# CY8C4248AZI_L485 register map
File version: 0.1
PSoC 4200L
Registers are 32-bit, read-write, no defined reset value unless marked. A register's access mark holds for its fields unless they carry their own. Offsets are from the block's base; lines under a group give offsets from that group; [hi:lo] are bit positions; {n}, {i} and the like mark numbered series; 'fields as' and 'values as' point back to an identical list; <NAME> marks a mode.

## Memory map
0x00000000 QuadDec
0x00000000 QuadDec_Cnt16
0x00000000 Timer_PWM
0x00000000 ADC_SAR_Seq_1 — Sequencing SAR ADC
0x00000000 PWM_Motor
0x00000000 I2C — Serial Communication Block
0x00000000 DMAC — DMAC Registers
0x00000000 Status_Reg_Switches
0x00000000 CAN
0x00000000 Can_addr
0x00000000 UART — Serial Communication Block

## QuadDec
Base 0x00000000
0x400F0002 QuadDec_Cnt16_COUNTER 16-bit — Counter value
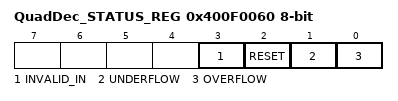
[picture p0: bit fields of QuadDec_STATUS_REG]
0x400F0060 QuadDec_STATUS_REG 8-bit — Quadrature Decoder Status Register
  [3] INVALID_IN ro — Invalid state transition on the A and B inputs
  [2] RESET ro — Counter Reset due index
  [1] UNDERFLOW ro — Counter underflow
  [0] OVERFLOW ro — Counter overflow

## QuadDec_Cnt16
Base 0x00000000; alternate view of QuadDec
0x400F0002 QuadDec_Cnt16_COUNTER 16-bit — UDB.A0 - Current Counter Value
0x400F0022 QuadDec_Cnt16_PERIOD 16-bit — UDB.D0 - Assigned Period
0x400F0032 QuadDec_Cnt16_COMPARE 16-bit — UDB.D1 - Assigned Compare Value
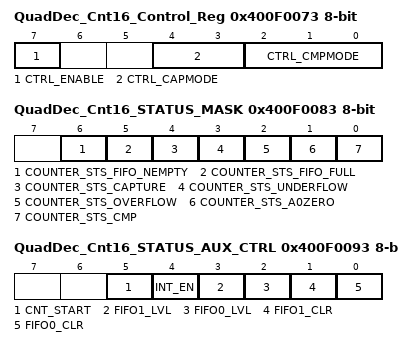
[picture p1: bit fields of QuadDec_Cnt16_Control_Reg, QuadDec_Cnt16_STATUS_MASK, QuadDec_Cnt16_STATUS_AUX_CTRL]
0x400F0073 QuadDec_Cnt16_Control_Reg 8-bit — UDB Control Register - Assigned Control Register Value
  [7] CTRL_ENABLE — Enable Counter
  [4:3] CTRL_CAPMODE — Capture mode
  [2:0] CTRL_CMPMODE — Compare mode
0x400F0083 QuadDec_Cnt16_STATUS_MASK 8-bit — UDB Status bits Interrupt Mask Enable Register
  [6] COUNTER_STS_FIFO_NEMPTY — FIFO Not Empty Status
  [5] COUNTER_STS_FIFO_FULL — FIFO Full Status
  [4] COUNTER_STS_CAPTURE — Capture Status
  [3] COUNTER_STS_UNDERFLOW — Underflow status
  [2] COUNTER_STS_OVERFLOW — Overflow status
  [1] COUNTER_STS_A0ZERO — A0 Zero ouput status
  [0] COUNTER_STS_CMP — Compare output status
0x400F0093 QuadDec_Cnt16_STATUS_AUX_CTRL 8-bit — UDB Auxilliary Control Register
  [5] CNT_START — FIFO0 clear
    0=E_CNT_START0 (Disable counter); 1=E_CNT_START1 (Enable counter)
  [4] INT_EN
    0=E_INT_EN0 (Interrupt disabled); 1=E_INT_EN1 (Interrupt enabled)
  [3] FIFO1_LVL — FIFO level
    0=E_FIFO_LVL_0 (FIFO LVL: input mode: FIFO not full; output mode: FIFO not empty); 1=E_FIFO_LVL_1 (FIFO LVL: input mode: FIFO at least 1/2 empty; output mode: FIFO at least 1/2 full)
  [2] FIFO0_LVL — FIFO level
    values as FIFO1_LVL
  [1] FIFO1_CLR — FIFO1 clear
    0=E_FIFO_CLR_0 (Normal FIFO operation); 1=E_FIFO_CLR_1 (Clear FIFO state)
  [0] FIFO0_CLR — FIFO0 clear
    values as FIFO1_CLR

## Timer_PWM
Base 0x00000000
0x400F0004 Timer_PWM_COUNTER 24-bit — UDB.A0 - Current Down Counter Value
0x400F0024 Timer_PWM_PERIOD 24-bit — UDB.D0 - Assigned Period
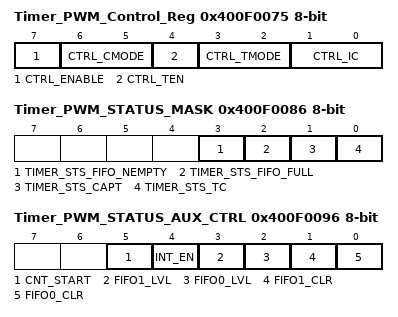
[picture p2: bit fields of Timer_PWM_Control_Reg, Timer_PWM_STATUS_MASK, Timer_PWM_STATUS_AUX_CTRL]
0x400F0075 Timer_PWM_Control_Reg 8-bit — UDB Control Register - Assigned Control Register Value
  [7] CTRL_ENABLE — Enable the Timer
  [6:5] CTRL_CMODE — Capture Mode
  [4] CTRL_TEN — Trigger Enable Bit
  [3:2] CTRL_TMODE — Trigger Mode
  [1:0] CTRL_IC — Interrupt Count
0x400F0086 Timer_PWM_STATUS_MASK 8-bit — UDB Status bits Interrupt Mask Enable Register
  [3] TIMER_STS_FIFO_NEMPTY ro — FIFO Empty status
  [2] TIMER_STS_FIFO_FULL ro — FIFO Full Status
  [1] TIMER_STS_CAPT ro — Enables the Interrupt on Capture
  [0] TIMER_STS_TC ro — Enables the Interrupt on TC
0x400F0096 Timer_PWM_STATUS_AUX_CTRL 8-bit — UDB Auxilliary Control Register
  [5] CNT_START — FIFO0 clear
    0=E_CNT_START0 (Disable counter); 1=E_CNT_START1 (Enable counter)
  [4] INT_EN
    0=E_INT_EN0 (Interrupt disabled); 1=E_INT_EN1 (Interrupt enabled)
  [3] FIFO1_LVL — FIFO level
    0=E_FIFO_LVL_0 (FIFO LVL: input mode: FIFO not full; output mode: FIFO not empty); 1=E_FIFO_LVL_1 (FIFO LVL: input mode: FIFO at least 1/2 empty; output mode: FIFO at least 1/2 full)
  [2] FIFO0_LVL — FIFO level
    values as FIFO1_LVL
  [1] FIFO1_CLR — FIFO1 clear
    0=E_FIFO_CLR_0 (Normal FIFO operation); 1=E_FIFO_CLR_1 (Clear FIFO state)
  [0] FIFO0_CLR — FIFO0 clear
    values as FIFO1_CLR
